AUTOSAR XML (schema 4-2-1)
package /RootP_ASWC_SATELLITE_CORE1_AppASILB
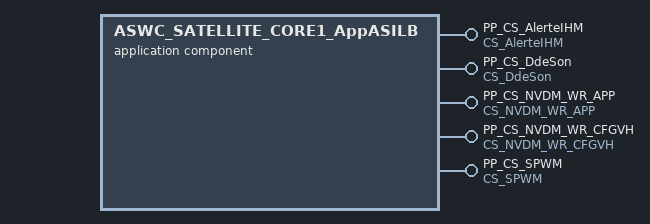
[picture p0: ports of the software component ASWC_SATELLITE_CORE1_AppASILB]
  application sw component type ASWC_SATELLITE_CORE1_AppASILB
    5 x provide port:
      PP_CS_AlerteIHM: server-com-spec{operation=Cmd, queue-length=1}, provided-interface=CS_AlerteIHM
      PP_CS_DdeSon: server-com-spec{operation=Cmd, queue-length=1}, provided-interface=CS_DdeSon
      PP_CS_NVDM_WR_APP: server-com-spec{operation=NvDM_WrApp_Block, queue-length=1}, provided-interface=CS_NVDM_WR_APP
      PP_CS_NVDM_WR_CFGVH: server-com-spec{operation=NvDM_WrCfgVh_Block, queue-length=1}, provided-interface=CS_NVDM_WR_CFGVH
      PP_CS_SPWM: server-com-spec{operation=Set, queue-length=1}, provided-interface=CS_SPWM
    behavior IB_ASWC_SATELLITE_CORE1_AppASILB: handle-termination-and-restart=NO-SUPPORT
      5 x operation invoked event:
        CS_AlerteIHM_Cmd_OIE_CORE1_AppASILB: start-on-event=RUNS_AlerteIHM_Cmd_CORE1_AppASILB, operation=PP_CS_AlerteIHM.Cmd
        CS_DdeSon_Cmd_OIE_CORE1_AppASILB: start-on-event=RUNS_DdeSon_Cmd_CORE1_AppASILB, operation=PP_CS_DdeSon.Cmd
        CS_NVDM_WR_APP_NvDM_WrApp_Block_OIE_CORE1_AppASILB: start-on-event=RUNS_NVDM_WR_APP_NvDM_WrApp_Block_CORE1_AppASILB, operation=PP_CS_NVDM_WR_APP.NvDM_WrApp_Block
        CS_NVDM_WR_CFGVH_NvDM_WrCfgVh_Block_OIE_CORE1_AppASILB: start-on-event=RUNS_NVDM_WR_CFGVH_NvDM_WrCfgVh_Block_CORE1_AppASILB, operation=PP_CS_NVDM_WR_CFGVH.NvDM_WrCfgVh_Block
        CS_SPWM_Set_OIE_CORE1_AppASILB: start-on-event=RUNS_SPWM_Set_CORE1_AppASILB, operation=PP_CS_SPWM.Set
      5 x runnable:
        RUNS_AlerteIHM_Cmd_CORE1_AppASILB
        RUNS_DdeSon_Cmd_CORE1_AppASILB
        RUNS_NVDM_WR_APP_NvDM_WrApp_Block_CORE1_AppASILB
        RUNS_NVDM_WR_CFGVH_NvDM_WrCfgVh_Block_CORE1_AppASILB
        RUNS_SPWM_Set_CORE1_AppASILB
  swc implementation ASWC_SATELLITE_CORE1_AppASILB_Impl: programming-language=C, sw-version=1.0.0, vendor-id=0, behavior=IB_ASWC_SATELLITE_CORE1_AppASILB
    code-descriptors:
      code SRC: artifact-descriptors=autosar-engineering-object={short-label=EngObject, category=SWSRC}
    resource consumption Resources
      memory section CODE: sw-addrmethod=CODE_ASWC_SATELLITE_CORE1_AppASILB
  sw addr method CODE_ASWC_SATELLITE_CORE1_AppASILB: memory-allocation-keyword-policy=ADDR-METHOD-SHORT-NAME-AND-ALIGNMENT, section-type=CODE
